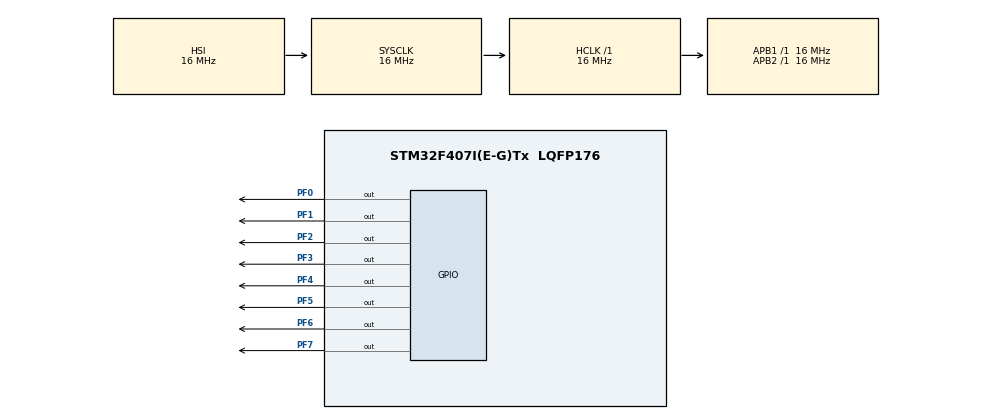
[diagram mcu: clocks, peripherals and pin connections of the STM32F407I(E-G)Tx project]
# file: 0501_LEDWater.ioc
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Mcu.Family=STM32F4
Mcu.Name=STM32F407I(E-G)Tx
Mcu.Package=LQFP176
NVIC.PriorityGroup=NVIC_PRIORITYGROUP_4
PA13.Mode=Serial_Wire
PA13.Signal=SYS_JTMS-SWDIO
PA14.Mode=Serial_Wire
PA14.Signal=SYS_JTCK-SWCLK
PF0.GPIO_ModeDefaultOutputPP=GPIO_MODE_OUTPUT_PP
PF0.GPIO_PuPd=GPIO_NOPULL
PF0.GPIO_Speed=GPIO_SPEED_FREQ_LOW
PF0.PinState=GPIO_PIN_SET
PF0.Signal=GPIO_Output
PF1.GPIO_ModeDefaultOutputPP=GPIO_MODE_OUTPUT_PP
PF1.GPIO_PuPd=GPIO_NOPULL
PF1.GPIO_Speed=GPIO_SPEED_FREQ_LOW
PF1.PinState=GPIO_PIN_SET
PF1.Signal=GPIO_Output
PF2.GPIO_ModeDefaultOutputPP=GPIO_MODE_OUTPUT_PP
PF2.GPIO_PuPd=GPIO_NOPULL
PF2.GPIO_Speed=GPIO_SPEED_FREQ_LOW
PF2.PinState=GPIO_PIN_SET
PF2.Signal=GPIO_Output
PF3.GPIO_ModeDefaultOutputPP=GPIO_MODE_OUTPUT_PP
PF3.GPIO_PuPd=GPIO_NOPULL
PF3.GPIO_Speed=GPIO_SPEED_FREQ_LOW
PF3.PinState=GPIO_PIN_SET
PF3.Signal=GPIO_Output
PF4.GPIO_ModeDefaultOutputPP=GPIO_MODE_OUTPUT_PP
PF4.GPIO_PuPd=GPIO_NOPULL
PF4.GPIO_Speed=GPIO_SPEED_FREQ_LOW
PF4.PinState=GPIO_PIN_SET
PF4.Signal=GPIO_Output
PF5.GPIO_ModeDefaultOutputPP=GPIO_MODE_OUTPUT_PP
PF5.GPIO_PuPd=GPIO_NOPULL
PF5.GPIO_Speed=GPIO_SPEED_FREQ_LOW
PF5.PinState=GPIO_PIN_SET
PF5.Signal=GPIO_Output
PF6.GPIO_ModeDefaultOutputPP=GPIO_MODE_OUTPUT_PP
PF6.GPIO_PuPd=GPIO_NOPULL
PF6.GPIO_Speed=GPIO_SPEED_FREQ_LOW
PF6.PinState=GPIO_PIN_SET
PF6.Signal=GPIO_Output
PF7.GPIO_ModeDefaultOutputPP=GPIO_MODE_OUTPUT_PP
PF7.GPIO_PuPd=GPIO_NOPULL
PF7.GPIO_Speed=GPIO_SPEED_FREQ_LOW
PF7.PinState=GPIO_PIN_SET
PF7.Signal=GPIO_Output
PH0-OSC_IN.Mode=HSE-External-Oscillator
PH0-OSC_IN.Signal=RCC_OSC_IN
PH1-OSC_OUT.Mode=HSE-External-Oscillator
PH1-OSC_OUT.Signal=RCC_OSC_OUT
ProjectManager.HeapSize=0x200
ProjectManager.StackSize=0x400
ProjectManager.TargetToolchain=MDK-ARM V5.32
RCC.48MHZClocksFreq_Value=65625000
RCC.AHBFreq_Value=16000000
RCC.APB1Freq_Value=16000000
RCC.APB1TimFreq_Value=16000000
RCC.APB2Freq_Value=16000000
RCC.APB2TimFreq_Value=16000000
RCC.CortexFreq_Value=16000000
RCC.HCLKFreq_Value=16000000
RCC.HSE_VALUE=25000000
RCC.HSI_VALUE=16000000
RCC.LSE_VALUE=32768
RCC.PLLN=168
RCC.PLLSourceVirtual=RCC_PLLSOURCE_HSE
RCC.SYSCLKFreq_VALUE=16000000
RCC.VCOOutputFreq_Value=262500000
board=custom

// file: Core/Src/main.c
/* USER CODE BEGIN Header */
/**
  ******************************************************************************
  * @file           : main.c
  * @brief          : Main program body
  ******************************************************************************
  * @attention
  *
  * Copyright (c) 2026 STMicroelectronics.
  * All rights reserved.
  *
  * This software is licensed under terms that can be found in the LICENSE file
  * in the root directory of this software component.
  * If no LICENSE file comes with this software, it is provided AS-IS.
  *
  ******************************************************************************
  */
/* USER CODE END Header */
#include "main.h"
#include "gpio.h"

void SystemClock_Config(void);

int main(void)
{

  /* MCU Configuration--------------------------------------------------------*/

  /* Reset of all peripherals, Initializes the Flash interface and the Systick. */
  HAL_Init();

  /* Configure the system clock */
  SystemClock_Config();

  /* Initialize all configured peripherals */
  MX_GPIO_Init();

  /* Infinite loop */
  while (1)
  {

    /* USER CODE BEGIN 3 */
		static uint8_t tab[] = {0xFE,0xFD,0xFB,0xF7,0xEF,0xDF,0xBF,0x7F};
static uint8_t i=0;
GPIOF->ODR = tab[i];
HAL_Delay(1000);
i++;
if(i >= 8)
{
    i = 0;
}
  }
  /* USER CODE END 3 */
}

void SystemClock_Config(void)
{
  RCC_OscInitTypeDef RCC_OscInitStruct = {0};
  RCC_ClkInitTypeDef RCC_ClkInitStruct = {0};

  /** Configure the main internal regulator output voltage
  */
  __HAL_RCC_PWR_CLK_ENABLE();
  __HAL_PWR_VOLTAGESCALING_CONFIG(PWR_REGULATOR_VOLTAGE_SCALE1);

  /** Initializes the RCC Oscillators according to the specified parameters
  * in the RCC_OscInitTypeDef structure.
  */
  RCC_OscInitStruct.OscillatorType = RCC_OSCILLATORTYPE_HSI;
  RCC_OscInitStruct.HSIState = RCC_HSI_ON;
  RCC_OscInitStruct.HSICalibrationValue = RCC_HSICALIBRATION_DEFAULT;
  RCC_OscInitStruct.PLL.PLLState = RCC_PLL_NONE;
  if (HAL_RCC_OscConfig(&RCC_OscInitStruct) != HAL_OK)
  {
    Error_Handler();
  }

  /** Initializes the CPU, AHB and APB buses clocks
  */
  RCC_ClkInitStruct.ClockType = RCC_CLOCKTYPE_HCLK|RCC_CLOCKTYPE_SYSCLK
                              |RCC_CLOCKTYPE_PCLK1|RCC_CLOCKTYPE_PCLK2;
  RCC_ClkInitStruct.SYSCLKSource = RCC_SYSCLKSOURCE_HSI;
  RCC_ClkInitStruct.AHBCLKDivider = RCC_SYSCLK_DIV1;
  RCC_ClkInitStruct.APB1CLKDivider = RCC_HCLK_DIV1;
  RCC_ClkInitStruct.APB2CLKDivider = RCC_HCLK_DIV1;

  if (HAL_RCC_ClockConfig(&RCC_ClkInitStruct, FLASH_LATENCY_0) != HAL_OK)
  {
    Error_Handler();
  }
}

void Error_Handler(void)
{
  __disable_irq();
  while (1)
  {
  }
}
